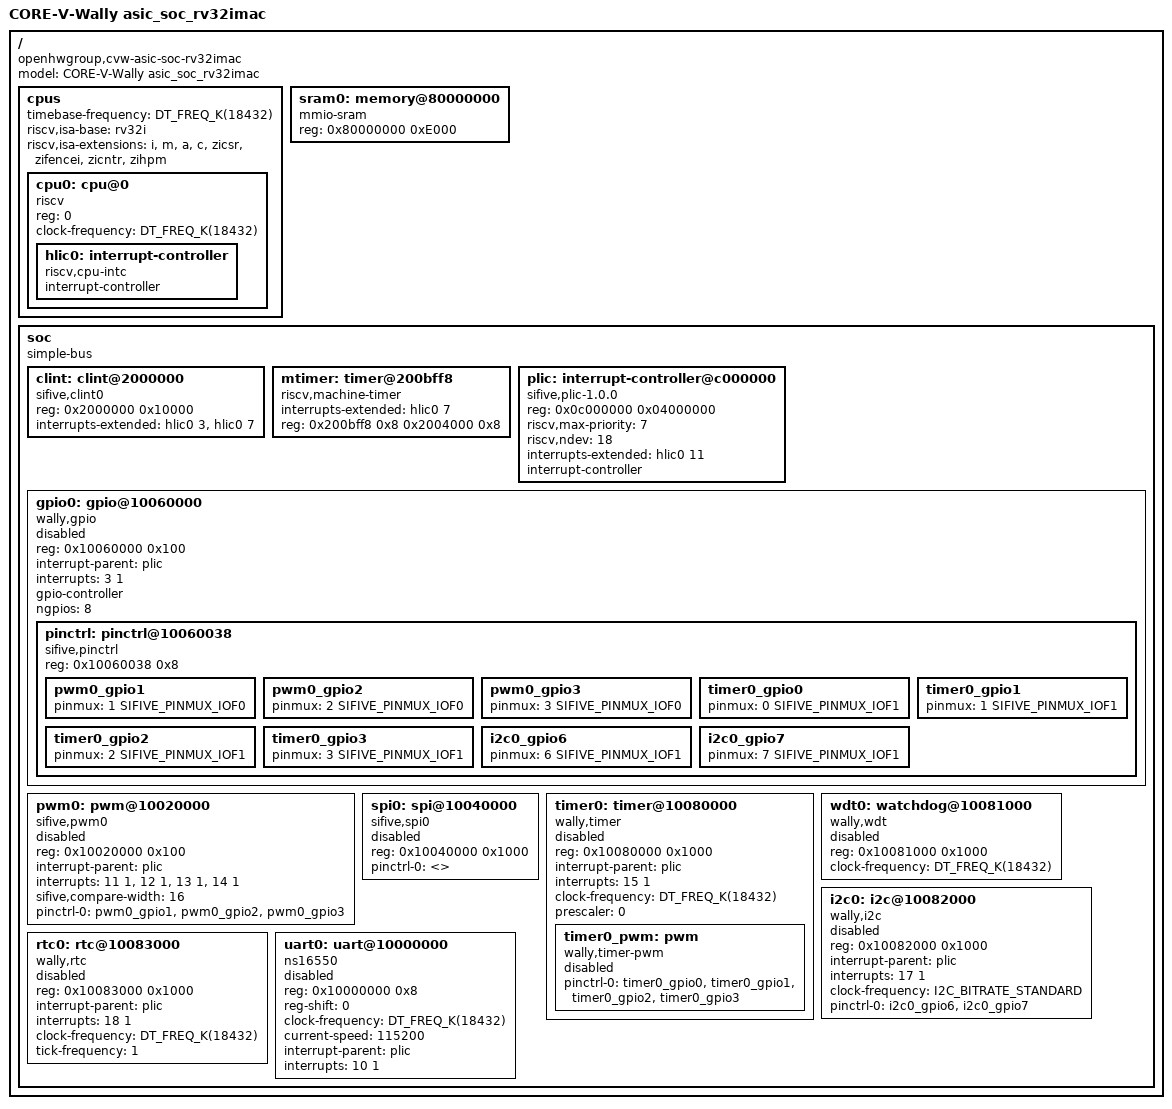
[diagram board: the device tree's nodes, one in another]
/* SPDX-License-Identifier: Apache-2.0
 * asic_soc_rv32imac (config/derivlist.txt; the addresses are those of its config.vh).  The 64 KiB RAM at
 * 0x80000000 ends with the 8 KiB the instruction trace buffer shares (TRACE_IN_RAM): Zephyr gets the first 56 KiB,
 * so the trace can be switched on without Zephyr or a user thread touching its area. */

#include <freq.h>
#include <zephyr/dt-bindings/i2c/i2c.h>

/ {
        #address-cells = <1>;
        #size-cells = <1>;
        compatible = "openhwgroup,cvw-asic-soc-rv32imac";
        model = "CORE-V-Wally asic_soc_rv32imac";

        cpus {
                #address-cells = <1>;
                #size-cells = <0>;
                timebase-frequency = <DT_FREQ_K(18432)>;
                riscv,isa-base = "rv32i";
                riscv,isa-extensions = "i", "m", "a", "c", "zicsr", "zifencei", "zicntr", "zihpm";

                cpu0: cpu@0 {
                        device_type = "cpu";
                        reg = <0>;
                        status = "okay";
                        compatible = "riscv";
                        clock-frequency = <DT_FREQ_K(18432)>;

                        hlic0: interrupt-controller {
                                compatible = "riscv,cpu-intc";
                                #address-cells = <0>;
                                #interrupt-cells = <1>;
                                interrupt-controller;
                        };
                };
        };

        sram0: memory@80000000 {
                compatible = "mmio-sram";
                reg = <0x80000000 0xE000>;
        };

        soc {
                #address-cells = <1>;
                #size-cells = <1>;
                compatible = "simple-bus";
                ranges;

                clint: clint@2000000 {
                        compatible = "sifive,clint0";
                        reg = <0x2000000 0x10000>;
                        interrupts-extended = <&hlic0 3 &hlic0 7>;
                };

                mtimer: timer@200bff8 {
                        compatible = "riscv,machine-timer";
                        interrupts-extended = <&hlic0 7>;
                        reg = <0x200bff8 0x8 0x2004000 0x8>;
                        reg-names = "mtime", "mtimecmp";
                };

                plic: interrupt-controller@c000000 {
                        compatible = "sifive,plic-1.0.0";
                        reg = <0x0c000000 0x04000000>;
                        riscv,max-priority = <7>;
                        riscv,ndev = <18>;
                        interrupts-extended = <&hlic0 11>;
                        interrupt-controller;
                        #address-cells = <0>;
                        #interrupt-cells = <2>;
                };

                /* GPIO with the register map of the FE310's and one interrupt line (PLIC source 3) for all 8 pins:
                 * wally,gpio has one handler for them.  Its IOF registers (IOF_EN, IOF_SEL) pick a pad's alternate
                 * function: the PWM comparators on GPIO0-3 (IOF0), the MCU timer on GPIO0-3 and I2C on GPIO6-7 (IOF1) */
                gpio0: gpio@10060000 {
                        compatible = "wally,gpio";
                        reg = <0x10060000 0x100>;
                        interrupt-parent = <&plic>;
                        interrupts = <3 1>;
                        gpio-controller;
                        #gpio-cells = <2>;
                        ngpios = <8>;
                        status = "disabled";

                        #address-cells = <1>;
                        #size-cells = <1>;
                        ranges;

                        /* IOF_EN and IOF_SEL: the Zephyr pinctrl driver finds the pin count in its parent, the GPIO */
                        pinctrl: pinctrl@10060038 {
                                compatible = "sifive,pinctrl";
                                reg = <0x10060038 0x8>;
                        };
                };

                /* the FU540 PWM of Wally: comparator 0 sets the period, 1-3 are the outputs on GPIO1-3 (IOF0) */
                pwm0: pwm@10020000 {
                        compatible = "sifive,pwm0";
                        reg = <0x10020000 0x100>;
                        reg-names = "control";
                        interrupt-parent = <&plic>;
                        interrupts = <11 1>, <12 1>, <13 1>, <14 1>;
                        sifive,compare-width = <16>;
                        #pwm-cells = <2>;
                        pinctrl-0 = <&pwm0_gpio1 &pwm0_gpio2 &pwm0_gpio3>;
                        pinctrl-names = "default";
                        status = "disabled";
                };

                spi0: spi@10040000 {
                        compatible = "sifive,spi0";
                        reg = <0x10040000 0x1000>;
                        reg-names = "control";
                        #address-cells = <1>;
                        #size-cells = <0>;
                        /* SCK, MOSI, MISO and CS have pads of their own: an empty state, which the driver needs */
                        pinctrl-0 = <>;
                        pinctrl-names = "default";
                        status = "disabled";
                };

                /* the MCU peripherals (MCU_BASE 0x10080000, one 4 KiB page each: timer, watchdog, I2C, RTC).  I2C is IOF1 of
                 * GPIO6 (SCL) and GPIO7 (SDA), open drain with external pull-ups */
                /* general-purpose timer: four channels on GPIO0-3 (IOF1), PLIC source 15.  Its PWM outputs are the child
                 * node, which shares the counter and the pads with the sifive,pwm0 above (IOF0 on GPIO1-3): enable one */
                timer0: timer@10080000 {
                        compatible = "wally,timer";
                        reg = <0x10080000 0x1000>;
                        interrupt-parent = <&plic>;
                        interrupts = <15 1>;
                        clock-frequency = <DT_FREQ_K(18432)>;
                        prescaler = <0>;
                        status = "disabled";

                        timer0_pwm: pwm {
                                compatible = "wally,timer-pwm";
                                #pwm-cells = <3>;
                                pinctrl-0 = <&timer0_gpio0 &timer0_gpio1 &timer0_gpio2 &timer0_gpio3>;
                                pinctrl-names = "default";
                                status = "disabled";
                        };
                };

                wdt0: watchdog@10081000 {
                        compatible = "wally,wdt";
                        reg = <0x10081000 0x1000>;
                        clock-frequency = <DT_FREQ_K(18432)>;
                        status = "disabled";
                };

                i2c0: i2c@10082000 {
                        compatible = "wally,i2c";
                        reg = <0x10082000 0x1000>;
                        interrupt-parent = <&plic>;
                        interrupts = <17 1>;
                        #address-cells = <1>;
                        #size-cells = <0>;
                        clock-frequency = <I2C_BITRATE_STANDARD>;
                        pinctrl-0 = <&i2c0_gpio6 &i2c0_gpio7>;
                        pinctrl-names = "default";
                        status = "disabled";
                };

                /* real-time counter of seconds since 1970 with one alarm, PLIC source 18 */
                rtc0: rtc@10083000 {
                        compatible = "wally,rtc";
                        reg = <0x10083000 0x1000>;
                        interrupt-parent = <&plic>;
                        interrupts = <18 1>;
                        clock-frequency = <DT_FREQ_K(18432)>;
                        tick-frequency = <1>;
                        status = "disabled";
                };

                uart0: uart@10000000 {
                        compatible = "ns16550";
                        reg = <0x10000000 0x8>;
                        reg-shift = <0>;
                        clock-frequency = <DT_FREQ_K(18432)>;
                        current-speed = <115200>;
                        interrupt-parent = <&plic>;
                        interrupts = <10 1>;
                        status = "disabled";
                };
        };
};

#include <zephyr/dt-bindings/pinctrl/sifive-pinctrl.h>

&pinctrl {
        pwm0_gpio1: pwm0_gpio1 {
                pinmux = <1 SIFIVE_PINMUX_IOF0>;
        };
        pwm0_gpio2: pwm0_gpio2 {
                pinmux = <2 SIFIVE_PINMUX_IOF0>;
        };
        pwm0_gpio3: pwm0_gpio3 {
                pinmux = <3 SIFIVE_PINMUX_IOF0>;
        };
        timer0_gpio0: timer0_gpio0 {
                pinmux = <0 SIFIVE_PINMUX_IOF1>;
        };
        timer0_gpio1: timer0_gpio1 {
                pinmux = <1 SIFIVE_PINMUX_IOF1>;
        };
        timer0_gpio2: timer0_gpio2 {
                pinmux = <2 SIFIVE_PINMUX_IOF1>;
        };
        timer0_gpio3: timer0_gpio3 {
                pinmux = <3 SIFIVE_PINMUX_IOF1>;
        };
        i2c0_gpio6: i2c0_gpio6 {
                pinmux = <6 SIFIVE_PINMUX_IOF1>;
        };
        i2c0_gpio7: i2c0_gpio7 {
                pinmux = <7 SIFIVE_PINMUX_IOF1>;
        };
};
